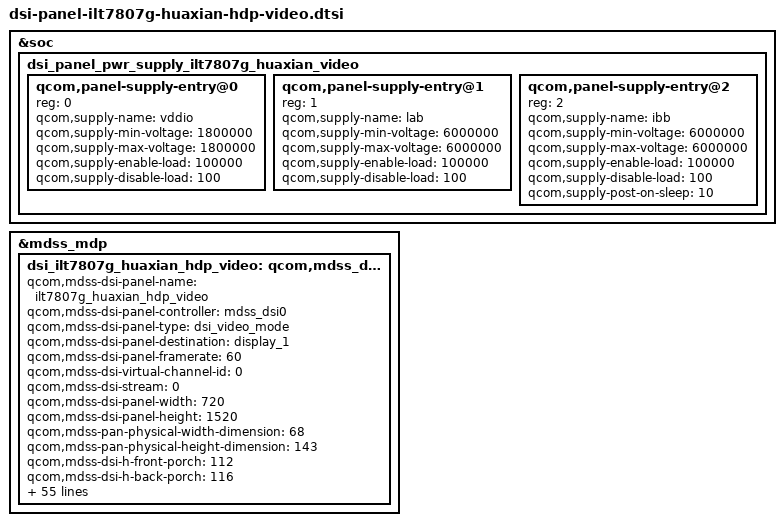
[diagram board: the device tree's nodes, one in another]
/***********************************************************
** Copyright (C), 2008-2016, OPPO Mobile Comm Corp., Ltd.
** ODM_WT_EDIT
** File: - panel_ilt7807g_huaxian_hdp_video.h
** Description: source ilt7807g huaxian panel config in kernel
**
** Version: 1.0
** Date : 2018/10/17
**
** ------------------------------- Revision History: -------------------------------
**  	<author>		<data> 	   <version >	       <desc>
**
****************************************************************/
&soc {
	dsi_panel_pwr_supply_ilt7807g_huaxian_video: dsi_panel_pwr_supply_ilt7807g_huaxian_video {
		#address-cells = <1>;
		#size-cells = <0>;

		qcom,panel-supply-entry@0 {
			reg = <0>;
			qcom,supply-name = "vddio";
			qcom,supply-min-voltage = <1800000>;
			qcom,supply-max-voltage = <1800000>;
			qcom,supply-enable-load = <100000>;
			qcom,supply-disable-load = <100>;
		};

		qcom,panel-supply-entry@1 {
			reg = <1>;
			qcom,supply-name = "lab";
			qcom,supply-min-voltage = <6000000>;
			qcom,supply-max-voltage = <6000000>;
			qcom,supply-enable-load = <100000>;
			qcom,supply-disable-load = <100>;
		};
		qcom,panel-supply-entry@2 {
			reg = <2>;
			qcom,supply-name = "ibb";
			qcom,supply-min-voltage = <6000000>;
			qcom,supply-max-voltage = <6000000>;
			qcom,supply-enable-load = <100000>;
			qcom,supply-disable-load = <100>;
			qcom,supply-post-on-sleep = <10>;
		};
	};
};
&mdss_mdp {
	dsi_ilt7807g_huaxian_hdp_video: qcom,mdss_dsi_ilt7807g_huaxian_hdp_video {
		qcom,mdss-dsi-panel-name = "ilt7807g_huaxian_hdp_video";
		qcom,mdss-dsi-panel-controller = <&mdss_dsi0>;
		qcom,mdss-dsi-panel-type = "dsi_video_mode";
		qcom,mdss-dsi-panel-destination = "display_1";
		qcom,mdss-dsi-panel-framerate = <60>;
		qcom,mdss-dsi-virtual-channel-id = <0>;
		qcom,mdss-dsi-stream = <0>;
		qcom,mdss-dsi-panel-width = <720>;
		qcom,mdss-dsi-panel-height = <1520>;
		qcom,mdss-pan-physical-width-dimension = <68>;
		qcom,mdss-pan-physical-height-dimension = <143>;
		qcom,mdss-dsi-h-front-porch = <112>;
		qcom,mdss-dsi-h-back-porch = <116>;
		qcom,mdss-dsi-h-pulse-width = <12>;
		qcom,mdss-dsi-h-sync-skew = <0>;
		qcom,mdss-dsi-v-back-porch = <6>;
		qcom,mdss-dsi-v-front-porch = <32>;
		qcom,mdss-dsi-v-pulse-width = <2>;
		qcom,mdss-dsi-h-left-border = <0>;
		qcom,mdss-dsi-h-right-border = <0>;
		qcom,mdss-dsi-v-top-border = <0>;
		qcom,mdss-dsi-v-bottom-border = <0>;
		qcom,mdss-dsi-bpp = <24>;
		qcom,mdss-dsi-color-order = "rgb_swap_rgb";
		qcom,mdss-dsi-underflow-color = <0xff>;
		qcom,mdss-dsi-border-color = <0>;
		qcom,mdss-dsi-on-command = [
					39 01 00 00 00 00 04 FF 78 07 01
					39 01 00 00 00 00 02 00 43
					39 01 00 00 00 00 02 01 50
					39 01 00 00 00 00 02 02 08
					39 01 00 00 00 00 02 03 7B
					39 01 00 00 00 00 02 9A 00
					39 01 00 00 00 00 02 9C 00
					39 01 00 00 00 00 02 04 00
					39 01 00 00 00 00 02 05 00
					39 01 00 00 00 00 02 06 00
					39 01 00 00 00 00 02 07 00
					39 01 00 00 00 00 02 08 83
					39 01 00 00 00 00 02 09 04
					39 01 00 00 00 00 02 0A 30
					39 01 00 00 00 00 02 0B 01
					39 01 00 00 00 00 02 0C 08
					39 01 00 00 00 00 02 0E 7B
					39 01 00 00 00 00 02 31 07
					39 01 00 00 00 00 02 32 07
					39 01 00 00 00 00 02 33 07
					39 01 00 00 00 00 02 34 07
					39 01 00 00 00 00 02 35 07
					39 01 00 00 00 00 02 36 07
					39 01 00 00 00 00 02 37 07
					39 01 00 00 00 00 02 38 07
					39 01 00 00 00 00 02 39 07
					39 01 00 00 00 00 02 3A 07
					39 01 00 00 00 00 02 3B 3D
					39 01 00 00 00 00 02 3C 02
					39 01 00 00 00 00 02 3D 2E
					39 01 00 00 00 00 02 3E 2F
					39 01 00 00 00 00 02 3F 30
					39 01 00 00 00 00 02 40 41
					39 01 00 00 00 00 02 41 28
					39 01 00 00 00 00 02 42 24
					39 01 00 00 00 00 02 43 08
					39 01 00 00 00 00 02 44 11
					39 01 00 00 00 00 02 45 13
					39 01 00 00 00 00 02 46 10
					39 01 00 00 00 00 02 47 12
					39 01 00 00 00 00 02 48 01
					39 01 00 00 00 00 02 49 07
					39 01 00 00 00 00 02 4A 07
					39 01 00 00 00 00 02 4B 07
					39 01 00 00 00 00 02 4C 07
					39 01 00 00 00 00 02 4D 07
					39 01 00 00 00 00 02 4E 07
					39 01 00 00 00 00 02 4F 07
					39 01 00 00 00 00 02 50 07
					39 01 00 00 00 00 02 51 07
					39 01 00 00 00 00 02 52 07
					39 01 00 00 00 00 02 53 3D
					39 01 00 00 00 00 02 54 3D
					39 01 00 00 00 00 02 55 2E
					39 01 00 00 00 00 02 56 2F
					39 01 00 00 00 00 02 57 30
					39 01 00 00 00 00 02 58 41
					39 01 00 00 00 00 02 59 28
					39 01 00 00 00 00 02 5A 24
					39 01 00 00 00 00 02 5B 09
					39 01 00 00 00 00 02 5C 12
					39 01 00 00 00 00 02 5D 10
					39 01 00 00 00 00 02 5E 11
					39 01 00 00 00 00 02 5F 13
					39 01 00 00 00 00 02 60 01
					39 01 00 00 00 00 02 61 07
					39 01 00 00 00 00 02 62 07
					39 01 00 00 00 00 02 63 07
					39 01 00 00 00 00 02 64 07
					39 01 00 00 00 00 02 65 07
					39 01 00 00 00 00 02 66 07
					39 01 00 00 00 00 02 67 07
					39 01 00 00 00 00 02 68 07
					39 01 00 00 00 00 02 69 07
					39 01 00 00 00 00 02 6A 07
					39 01 00 00 00 00 02 6B 3D
					39 01 00 00 00 00 02 6C 02
					39 01 00 00 00 00 02 6D 2E
					39 01 00 00 00 00 02 6E 2F
					39 01 00 00 00 00 02 6F 30
					39 01 00 00 00 00 02 70 41
					39 01 00 00 00 00 02 71 28
					39 01 00 00 00 00 02 72 00
					39 01 00 00 00 00 02 73 09
					39 01 00 00 00 00 02 74 12
					39 01 00 00 00 00 02 75 10
					39 01 00 00 00 00 02 76 13
					39 01 00 00 00 00 02 77 11
					39 01 00 00 00 00 02 78 24
					39 01 00 00 00 00 02 79 07
					39 01 00 00 00 00 02 7A 07
					39 01 00 00 00 00 02 7B 07
					39 01 00 00 00 00 02 7C 07
					39 01 00 00 00 00 02 7D 07
					39 01 00 00 00 00 02 7E 07
					39 01 00 00 00 00 02 7F 07
					39 01 00 00 00 00 02 80 07
					39 01 00 00 00 00 02 81 07
					39 01 00 00 00 00 02 82 07
					39 01 00 00 00 00 02 83 3D
					39 01 00 00 00 00 02 84 3D
					39 01 00 00 00 00 02 85 2E
					39 01 00 00 00 00 02 86 2F
					39 01 00 00 00 00 02 87 30
					39 01 00 00 00 00 02 88 41
					39 01 00 00 00 00 02 89 28
					39 01 00 00 00 00 02 8A 00
					39 01 00 00 00 00 02 8B 08
					39 01 00 00 00 00 02 8C 11
					39 01 00 00 00 00 02 8D 13
					39 01 00 00 00 00 02 8E 12
					39 01 00 00 00 00 02 8F 10
					39 01 00 00 00 00 02 90 24
					39 01 00 00 00 00 02 92 10
					39 01 00 00 00 00 02 A0 45
					39 01 00 00 00 00 02 A1 44
					39 01 00 00 00 00 02 A2 43
					39 01 00 00 00 00 02 A3 43
					39 01 00 00 00 00 02 A4 01
					39 01 00 00 00 00 02 A5 50
					39 01 00 00 00 00 02 A6 20
					39 01 00 00 00 00 02 A7 50
					39 01 00 00 00 00 02 A8 10
					39 01 00 00 00 00 02 B0 20
					39 01 00 00 00 00 02 B1 00
					39 01 00 00 00 00 02 B2 02
					39 01 00 00 00 00 02 B3 00
					39 01 00 00 00 00 02 B4 0A
					39 01 00 00 00 00 02 C5 2A
					39 01 00 00 00 00 02 C6 A0
					39 01 00 00 00 00 02 C7 00
					39 01 00 00 00 00 02 C8 00
					39 01 00 00 00 00 02 C9 00
					39 01 00 00 00 00 02 CA 01
					39 01 00 00 00 00 02 D1 10
					39 01 00 00 00 00 02 D2 00
					39 01 00 00 00 00 02 D3 00
					39 01 00 00 00 00 02 D4 00
					39 01 00 00 00 00 02 D5 01
					39 01 00 00 00 00 02 D6 29
					39 01 00 00 00 00 02 D7 00
					39 01 00 00 00 00 02 D8 00
					39 01 00 00 00 00 02 D9 55
					39 01 00 00 00 00 02 DA 00
					39 01 00 00 00 00 02 DB 00
					39 01 00 00 00 00 02 DC 00
					39 01 00 00 00 00 02 DD 00
					39 01 00 00 00 00 02 DE 00
					39 01 00 00 00 00 02 DF 00
					39 01 00 00 00 00 02 E0 28
					39 01 00 00 00 00 02 E1 04
					39 01 00 00 00 00 02 E2 00
					39 01 00 00 00 00 02 E3 01
					39 01 00 00 00 00 02 E4 21
					39 01 00 00 00 00 02 E5 09
					39 01 00 00 00 00 02 E6 22
					39 01 00 00 00 00 02 E7 00
					39 01 00 00 00 00 02 ED 45
					39 01 00 00 00 00 02 EF 30
					39 01 00 00 00 00 02 F0 00
					39 01 00 00 00 00 04 FF 78 07 02
					39 01 00 00 00 00 02 06 AC
					39 01 00 00 00 00 02 07 AC
					39 01 00 00 00 00 02 78 16
					39 01 00 00 00 00 02 79 16
					39 01 00 00 00 00 02 40 0D
					39 01 00 00 00 00 02 41 00
					39 01 00 00 00 00 02 42 08
					39 01 00 00 00 00 02 43 1F
					39 01 00 00 00 00 02 46 22
					39 01 00 00 00 00 02 53 04
					39 01 00 00 00 00 02 54 05
					39 01 00 00 00 00 02 56 02
					39 01 00 00 00 00 02 5D 07
					39 01 00 00 00 00 02 76 14
					39 01 00 00 00 00 02 80 32
					39 01 00 00 00 00 02 F4 00
					39 01 00 00 00 00 02 F5 00
					39 01 00 00 00 00 02 F6 00
					39 01 00 00 00 00 02 F7 00
					39 01 00 00 00 00 04 FF 78 07 03
					39 01 00 00 00 00 02 83 30
					39 01 00 00 00 00 02 84 01
					39 01 00 00 00 00 04 FF 78 07 05
					39 01 00 00 00 00 02 27 44
					39 01 00 00 00 00 02 28 54
					39 01 00 00 00 00 02 A0 44
					39 01 00 00 00 00 02 A2 54
					39 01 00 00 00 00 02 03 00
					39 01 00 00 00 00 02 04 7F
					39 01 00 00 00 00 02 63 8D
					39 01 00 00 00 00 02 64 8D
					39 01 00 00 00 00 02 69 6A
					39 01 00 00 00 00 02 6B 42
					39 01 00 00 00 00 02 68 65
					39 01 00 00 00 00 02 6A 3D
					39 01 00 00 00 00 04 FF 78 07 06
					39 01 00 00 00 00 02 06 C4
					39 01 00 00 00 00 02 07 F5
					39 01 00 00 00 00 02 D6 67
					39 01 00 00 00 00 02 DD 10
					39 01 00 00 00 00 02 7C 40
					39 01 00 00 00 00 02 2E 01
					39 01 00 00 00 00 02 C0 F7
					39 01 00 00 00 00 02 C1 02
					39 01 00 00 00 00 02 C2 07
					39 01 00 00 00 00 02 C3 06
					39 01 00 00 00 00 02 11 03
					39 01 00 00 00 00 02 12 10
					39 01 00 00 00 00 02 13 23
					39 01 00 00 00 00 02 14 41
					39 01 00 00 00 00 02 15 E0
					39 01 00 00 00 00 02 16 40
					39 01 00 00 00 00 02 17 47
					39 01 00 00 00 00 02 18 3A
					39 01 00 00 00 00 02 B4 BB
					39 01 00 00 00 00 02 B5 15
					39 01 00 00 00 00 04 FF 78 07 07
					39 01 00 00 00 00 02 06 90
					39 01 00 00 00 00 04 FF 78 07 08
					39 01 00 00 00 00 29 E0 00 00 16 3D 00 5E 77 8F 00 A4 B7 C7 15 01 2E 6F 25 9E EC 23 2A 24 5C 9D 3A C5 FB 21 3F 4C 54 68 3F 72 8C 96 3F B9 D5 E6
					39 01 00 00 00 00 29 E1 00 00 16 3D 00 5E 77 8F 00 A4 B7 C7 15 01 2E 6F 25 9E EC 23 2A 24 5C 9D 3A C5 FB 21 3F 4C 54 68 3F 72 8C 96 3F B9 D5 E6
					39 01 00 00 00 00 04 FF 78 07 09
					39 01 00 00 00 00 29 E0 00 00 17 3F 00 5F 79 91 00 A5 B8 C9 15 02 2E 6F 25 9E EB 22 2A 23 5B 9C 3A C5 FA 21 3F 4C 55 68 3F 73 8F 9A 3F BE D8 E6
					39 01 00 00 00 00 29 E1 00 00 17 3F 00 5F 79 91 00 A5 B8 C9 15 02 2E 6F 25 9E EB 22 2A 23 5B 9C 3A C5 FA 21 3F 4C 55 68 3F 73 8F 9A 3F BE D8 E6
					39 01 00 00 00 00 04 FF 78 07 0A
					39 01 00 00 00 00 29 E0 00 00 1D 4A 00 6D 89 A1 00 B5 C8 D8 15 10 3B 7A 25 A6 F3 27 2A 28 60 A0 3A C7 FD 23 3F 4D 56 6A 3F 74 8F 9A 3F BB D6 E6
					39 01 00 00 00 00 29 E1 00 00 1D 4A 00 6D 89 A1 00 B5 C8 D8 15 10 3B 7A 25 A6 F3 27 2A 28 60 A0 3A C7 FD 23 3F 4D 56 6A 3F 74 8F 9A 3F BB D6 E6
					39 01 00 00 00 00 04 FF 78 07 0E
					39 01 00 00 00 00 02 00 A3
					39 01 00 00 00 00 02 4D 90
					39 01 00 00 00 00 02 47 80
					39 01 00 00 00 00 02 41 08
					39 01 00 00 00 00 02 43 6E
					39 01 00 00 00 00 02 49 7E
					39 01 00 00 00 00 02 49 7E
					39 01 00 00 00 00 02 B0 31
					39 01 00 00 00 00 02 B1 91
					39 01 00 00 00 00 02 B3 00
					39 01 00 00 00 00 02 B4 33
					39 01 00 00 00 00 02 45 09
					39 01 00 00 00 00 02 46 E6
					39 01 00 00 00 00 02 BC 04
					39 01 00 00 00 00 02 BD FC
					39 01 00 00 00 00 02 C0 34
					39 01 00 00 00 00 02 C6 91
					39 01 00 00 00 00 02 C7 91
					39 01 00 00 00 00 02 C8 91
					39 01 00 00 00 00 02 C9 91
					39 01 00 00 00 00 02 D2 00
					39 01 00 00 00 00 02 D3 A8
					39 01 00 00 00 00 02 D4 00
					39 01 00 00 00 00 02 D5 A8
					39 01 00 00 00 00 02 D6 00
					39 01 00 00 00 00 02 D7 A8
					39 01 00 00 00 00 02 D8 00
					39 01 00 00 00 00 02 D9 A8
					39 01 00 00 00 00 02 E0 0A
					39 01 00 00 00 00 02 E1 00
					39 01 00 00 00 00 02 E2 08
					39 01 00 00 00 00 02 E3 1F
					39 01 00 00 00 00 02 E4 04
					39 01 00 00 00 00 02 E5 04
					39 01 00 00 00 00 02 E6 00
					39 01 00 00 00 00 02 E7 05
					39 01 00 00 00 00 02 E8 00
					39 01 00 00 00 00 02 E9 02
					39 01 00 00 00 00 02 EA 07
					39 01 00 00 00 00 02 07 21
					39 01 00 00 00 00 02 4B 09
					39 01 00 00 00 00 04 FF 78 07 0C
					39 01 00 00 00 00 02 00 1E
					39 01 00 00 00 00 02 01 1C
					39 01 00 00 00 00 02 02 1E
					39 01 00 00 00 00 02 03 1B
					39 01 00 00 00 00 02 04 1E
					39 01 00 00 00 00 02 05 1D
					39 01 00 00 00 00 02 06 1E
					39 01 00 00 00 00 02 07 1A
					39 01 00 00 00 00 02 08 1E
					39 01 00 00 00 00 02 09 1E
					39 01 00 00 00 00 02 0A 1E
					39 01 00 00 00 00 02 0B 19
					39 01 00 00 00 00 02 0C 1E
					39 01 00 00 00 00 02 0D 1F
					39 01 00 00 00 00 02 0E 1E
					39 01 00 00 00 00 02 0F 20
					39 01 00 00 00 00 02 10 1E
					39 01 00 00 00 00 02 11 18
					39 01 00 00 00 00 02 12 1E
					39 01 00 00 00 00 02 13 21
					39 01 00 00 00 00 04 FF 78 07 00
					39 01 00 00 00 00 03 68 05 00
					39 01 00 00 00 00 03 51 00 00
					39 01 00 00 00 00 02 53 24
					05 01 00 00 B4 00 02 11 00
					05 01 00 00 14 00 02 29 00];
		qcom,mdss-dsi-off-command = [05 01 00 00 14 00 02 28 00
					05 01 00 00 50 00 02 10 00];
		qcom,mdss-dsi-on-command-state = "dsi_lp_mode";
		qcom,mdss-dsi-off-command-state = "dsi_lp_mode";
		qcom,vddio-always-on-enabled;
		qcom,mdss-dsi-h-sync-pulse = <1>;
		qcom,mdss-dsi-traffic-mode = "burst_mode";
		qcom,panel-supply-entries = <&dsi_panel_pwr_supply_ilt7807g_huaxian_video>;
		//qcom,mdss-dsi-lane-map = "lane_map_0123";
		qcom,mdss-dsi-bllp-eof-power-mode;
		qcom,mdss-dsi-bllp-power-mode;
		qcom,mdss-dsi-lane-0-state;
		qcom,mdss-dsi-lane-1-state;
		qcom,mdss-dsi-lane-2-state;
		//qcom,mdss-dsi-lane-3-state;
		//qcom,mdss-dsi-panel-timings = [FB 38 26 00 6A 6C 2C 3C 2F 03 04 00];
		qcom,mdss-dsi-panel-timings-phy-v2 = [21 1D 07 08 04 03 04 A0
		21 1D 07 08 04 03 04 A0
		21 1D 07 08 04 03 04 A0
		21 1D 07 08 04 03 04 A0
		21 16 06 07 04 03 04 A0];
		qcom,mdss-dsi-t-clk-post = <0x0C>;
		qcom,mdss-dsi-t-clk-pre = <0x29>;
		qcom,mdss-dsi-bl-pmic-control-type = "bl_ctrl_dcs";
		qcom,mdss-dsi-bl-min-level = <1>;
		qcom,mdss-dsi-bl-max-level = <2047>;
		qcom,mdss-brightness-max-level = <2047>;
		qcom,blmap-size = <128>;
		qcom,blmap = <
			36 160
			16 223
			17 217
			19 202
			19 200
			20 178
			22 154
			22 147
			24 107
			24 89
			26 45
			27 0
			29 94
			29 95
			30 140
			33 256
			34 304
			36 443
			37 491
			40 654
			40 697
			43 883
			46 1091
			47 1127
			50 1359
			53 1617
			53 1634
			60 2209
			60 2230
			64 2570
			63 2552
			71 3341
			71 3319
			75 3751
			80 4221
			84 4733
			89 5290
			88 5181
			99 6530
			98 6402
			103 7077
			117 8786
			115 8624
			122 9477
			128 10396
			135 11387
			132 11025
			149 13556
			157 14788
			166 16114
			163 15631
			183 19005
			180 18449
			203 22329
			199 21691
			209 23447
			236 28211
			232 27428
			243 29580
			255 31880
			268 34335
			282 36965
			317 44054
			176 15600>;
		qcom,mdss-dsi-dma-trigger = "trigger_sw";
		qcom,mdss-dsi-mdp-trigger = "none";
		qcom,mdss-dsi-lp11-init;
		//qcom,mdss-dsi-init-delay-us = <50000>;
		qcom,mdss-dsi-reset-sequence = <1 10>, <0 5>, <1 10>;
		qcom,esd-check-enabled;
		qcom,mdss-dsi-panel-status-command = [06 01 00 01 00 00 01 0a];
		qcom,mdss-dsi-panel-status-command-state = "dsi_lp_mode";
		qcom,mdss-dsi-panel-status-read-length = <1>;
		qcom,mdss-dsi-panel-status-value = <0x9C>;
		qcom,mdss-dsi-panel-status-check-mode = "reg_read";
		qcom,mdss-dsi-tx-eot-append;
		//qcom,mdss-dsi-post-init-delay = <1>;
	};
};
